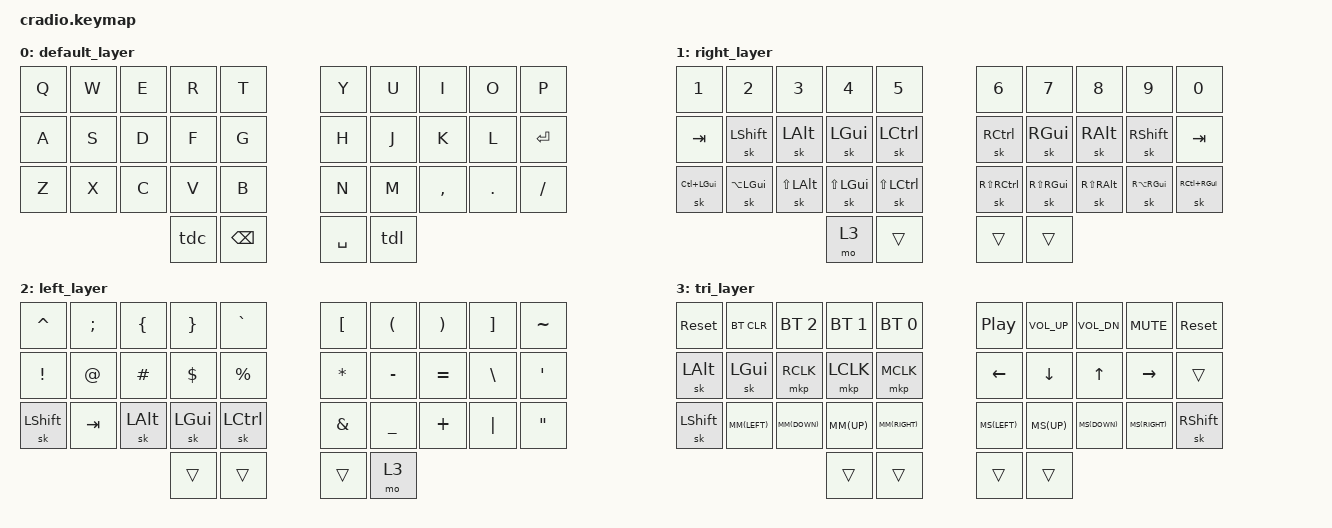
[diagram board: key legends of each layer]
// Copyright (c) 2022 The ZMK Contributors
// SPDX-License-Identifier: MIT

#include <behaviors.dtsi>
#include <dt-bindings/zmk/keys.h>
#include <dt-bindings/zmk/bt.h>
#include "zmk-helpers/helper.h"
#include "zmk-helpers/key-labels/34.h"

#define ZMK_POINTING_DEFAULT_MOVE_VAL 1500
#define ZMK_POINTING_DEFAULT_SCRL_VAL 15
#include <dt-bindings/zmk/pointing.h>


#define BTLD &bootloader
#define MM(dir) &mmv MOVE_##dir
#define MS(dir) &msc SCRL_##dir
#define THUMBS_L LH1 LH0 
#define THUMBS_R RH0 RH1
#define KEYS_L \
  LT4 LT3 LT2 LT1 LT0\
  LM4 LM3 LM2 LM1 LM0\
  LB4 LB3 LB2 LB1 LB0
#define KEYS_R \
  RT0 RT1 RT2 RT3 RT4\
  RM0 RM1 RM2 RM3 RM4\
  RB0 RB1 RB2 RB3 RB4

// Home row mods macro
#define HRML(k1,k2,k3,k4) &hml LSHFT k1  &hml LCTRL k2  &hml LALT k3  &hml LGUI k4
#define HRMR(k1,k2,k3,k4) &hmr RGUI k1  &hmr RALT k2  &hmr RCTRL k3  &hmr RSHFT k4

#define EXTRA_SLOW 40
#define SLOW 35
#define FAST 25
#define MEDIUM 30

&lt {
  flavor = "balanced";
  tapping-term-ms = <280>;
};

&sk {
  release-after-ms = <750>; 
};

/ {
    combos {
        compatible = "zmk,combos";
        combo_esc {
            timeout-ms = <MEDIUM>;
            require-prior-idle-ms = <145>;
            key-positions = <LM2 LM1>;
            bindings = <&kp ESC>;
            layers = <0>;
        };
        combo_colon {
            timeout-ms = <MEDIUM>;
            require-prior-idle-ms = <145>;
            key-positions = <RM2 RM1>;
            bindings = <&kp COLON>;
            layers = <0>;
        };
        combo_lctl {
            timeout-ms = <SLOW>;
            require-prior-idle-ms = <145>;
            slow-release;
            key-positions = <LH0 LM3>;
            bindings = <&sk LCTRL>;
            layers = <0>;
        };
        combo_rctl {
            timeout-ms = <SLOW>;
            require-prior-idle-ms = <145>;
            slow-release;
            key-positions = <RH0 RM3>;
            bindings = <&sk RCTRL>;
            layers = <0>;
        };
        combo_lshft {
            timeout-ms = <EXTRA_SLOW>;
            require-prior-idle-ms = <145>;
            slow-release;
            key-positions = <LH0 LM4>;
            bindings = <&sk LSHIFT>;
            layers = <0>;
        };
        combo_rshft {
            timeout-ms = <EXTRA_SLOW>;
            require-prior-idle-ms = <145>;
            slow-release;
            key-positions = <RH0 RM4>;
            bindings = <&sk RSHIFT>;
            layers = <0>;
        };
        combo_layers {
            timeout-ms = <SLOW>;
            require-prior-idle-ms = <145>;
            slow-release;
            key-positions = <RH1 LH1>;
            bindings = <&sl 3>;
            layers = <0>;
        };
    };
};

/ {
    behaviors {
      tdc: tap_dance_capsword {
            compatible = "zmk,behavior-tap-dance";
            #binding-cells = <0>;
            tapping-term-ms = <300>;
            bindings = <&sl 2>, <&caps_word>;
      };
      tdl: tap_dance_layer {
            compatible = "zmk,behavior-tap-dance";
            #binding-cells = <0>;
            tapping-term-ms = <200>;
            bindings = <&sl 1>, <&sl 3>;
      };
    };
    /* conditional_layers { */
    /*     compatible = "zmk,conditional-layers"; */
    /*     tri_layer { */
    /*         if-layers = <1 2>; */
    /*         then-layer = <3>; */
    /*     }; */
    /* }; */

    keymap {
        compatible = "zmk,keymap";
        default_layer {
            bindings = <
        //╭──────────┬──────────┬──────────┬──────────┬──────────╮   ╭──────────┬──────────┬──────────┬──────────┬──────────╮
        //│  Q       │  W       │  E       │  R       │  T       │   │  Y       │  U       │  I       │  O       │  P       │
            &kp Q     &kp W      &kp E      &kp R      &kp T          &kp Y      &kp U      &kp I      &kp O      &kp P
        //├──────────┼──────────┼──────────┼──────────┼──────────┤   ├──────────┼──────────┼──────────┼──────────┼──────────┤
        //│  A       │  S       │  D       │  F       │  G       │   │  H       │  J       │  K       │  L       │ ' "      │
            &kp A      &kp S      &kp D      &kp F     &kp G          &kp H      &kp J      &kp K      &kp L      &kp ENTER
        //├──────────┼──────────┼──────────┼──────────┼──────────┤   ├──────────┼──────────┼──────────┼──────────┼──────────┤
        //│  Z       │  X       │  C       │  V       │  B       │   │  N       │  M       │ , <      │ . >      │ / ?      │
            &kp Z      &kp X      &kp C      &kp V      &kp B          &kp N      &kp M      &kp COMMA  &kp DOT    &kp FSLH
        //╰──────────┴──────────┴──────────┼──────────┼──────────┤   ├──────────┼──────────┼──────────┴──────────┴──────────╯
                                              &tdc     &kp BSPC       &kp SPACE   &tdl 
        //                                 ╰──────────┴──────────╯   ╰──────────┴──────────╯
            >;
        };

        right_layer {
            bindings = <
        //╭──────────┬──────────┬──────────┬──────────┬──────────╮   ╭──────────┬──────────┬──────────┬──────────┬──────────╮
        //│          │          │          │          │          │   │          │          │          │          │          │
          &kp N1      &kp N2      &kp N3      &kp N4      &kp N5      &kp N6      &kp N7      &kp N8      &kp N9    &kp N0
        //├──────────┼──────────┼──────────┼──────────┼──────────┤   ├──────────┼──────────┼──────────┼──────────┼──────────┤
        //│          │          │          │          │          │   │          │          │          │          │          │
            &kp TAB  &sk LSHIFT   &sk LALT  &sk LGUI   &sk LCTRL      &sk RCTRL   &sk RGUI   &sk RALT   &sk RSHIFT &kp TAB 
        //├──────────┼──────────┼──────────┼──────────┼──────────┤   ├──────────┼──────────┼──────────┼──────────┼──────────┤
        //│          │          │          │          │          │   │          │          │          │          │          │
  &sk LC(LGUI) &sk LA(LGUI) &sk LS(LALT) &sk LS(LGUI) &sk LS(LCTRL) &sk RS(RCTRL) &sk RS(RGUI) &sk RS(RALT) &sk RA(RGUI) &sk RC(RGUI)
        //╰──────────┴──────────┴──────────┼──────────┼──────────┤   ├──────────┼──────────┼──────────┴──────────┴──────────╯
                                             &mo 3      &trans        &trans     &trans
        //                                 ╰──────────┴──────────╯   ╰──────────┴──────────╯
            >;
        };

        left_layer {
            bindings = <
        //╭──────────┬──────────┬──────────┬──────────┬──────────╮   ╭──────────┬──────────┬──────────┬──────────┬──────────╮
        //│    ^     │    ;     │     {    │     }    │    `     │   │     [    │     (    │  )       │  ]       │     ~    │ 
            &kp CARET &kp SEMI   &kp LBRC   &kp RBRC    &kp GRAVE      &kp LBKT   &kp LPAR   &kp RPAR    &kp RBKT  &kp TILDE   
        //├──────────┼──────────┼──────────┼──────────┼──────────┤   ├──────────┼──────────┼──────────┼──────────┼──────────┤
        //│  !       │  @       │  #       │  $       │  %       │   │  *       │  -       │  =       │  \       │  ' "     │
            &kp EXCL   &kp AT     &kp HASH   &kp DLLR   &kp PRCNT      &kp ASTRK  &kp MINUS  &kp EQUAL  &kp BSLH  &kp QUOT  
        //├──────────┼──────────┼──────────┼──────────┼──────────┤   ├──────────┼──────────┼──────────┼──────────┼──────────┤
        //│          │          │          │          │          │   │  &       │  _       │  +       │  │       │          │
           &sk LSHIFT  &kp TAB   &sk LALT  &sk LGUI   &sk LCTRL       &kp AMPS   &kp UNDER  &kp PLUS   &kp PIPE   &kp DQT
        //╰──────────┴──────────┴──────────┼──────────┼──────────┤   ├──────────┼──────────┼──────────┴──────────┴──────────╯
                                             &trans     &trans          &trans     &mo 3
        //                                 ╰──────────┴──────────╯   ╰──────────┴──────────╯
            >;
        };

        tri_layer {
            bindings = <
        //╭──────────┬──────────┬──────────┬──────────┬──────────╮   ╭──────────┬──────────┬──────────┬──────────┬──────────╮
        //│ RESET    │          │          │          │          │   │          │          │          │          │  RESET   │
      &sys_reset &bt BT_CLR &bt BT_SEL 2 &bt BT_SEL 1 &bt BT_SEL 0   &kp C_PP &kp C_VOL_UP &kp C_VOL_DN &kp C_MUTE &sys_reset
        //├──────────┼──────────┼──────────┼──────────┼──────────┤   ├──────────┼──────────┼──────────┼──────────┼──────────┤
        //│          │          │          │          │          │   │          │          │          │          │          │
            &sk LALT  &sk LGUI   &mkp RCLK  &mkp LCLK  &mkp MCLK       &kp LEFT   &kp DOWN   &kp UP   &kp RIGHT   &trans 
        //├──────────┼──────────┼──────────┼──────────┼──────────┤   ├──────────┼──────────┼──────────┼──────────┼──────────┤
        //│          │          │          │          │          │   │          │          │          │          │          │
          &sk LSHIFT  MM(LEFT)   MM(DOWN)    MM(UP)   MM(RIGHT)        MS(LEFT)   MS(UP)    MS(DOWN)   MS(RIGHT)  &sk RSHIFT      
        //╰──────────┴──────────┴──────────┼──────────┼──────────┤   ├──────────┼──────────┼──────────┴──────────┴──────────╯
                                             &trans     &trans         &trans     &trans
        //                                 ╰──────────┴──────────╯   ╰──────────┴──────────╯
            >;
        };

    };
};
